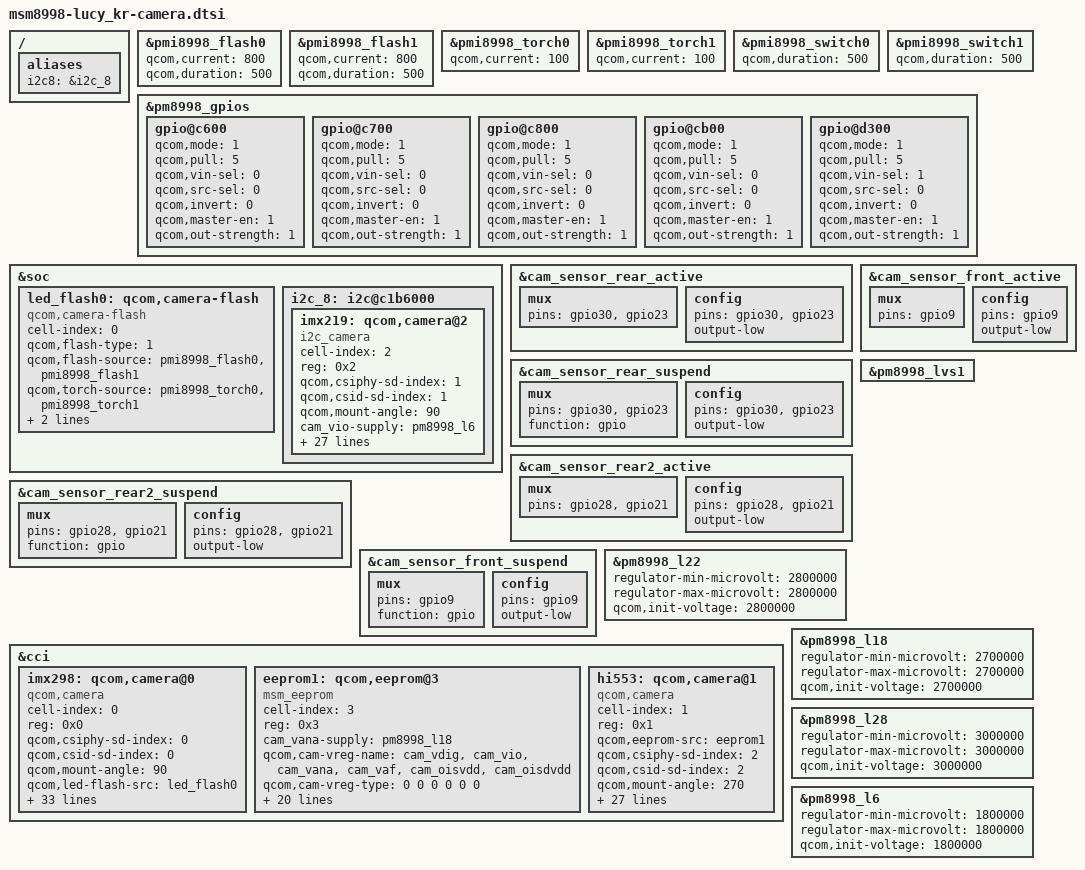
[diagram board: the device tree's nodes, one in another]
/*
 * Copyright (c) 2016, The Linux Foundation. All rights reserved.
 *
 * This program is free software; you can redistribute it and/or modify
 * it under the terms of the GNU General Public License version 2 and
 * only version 2 as published by the Free Software Foundation.
 *
 * This program is distributed in the hope that it will be useful,
 * but WITHOUT ANY WARRANTY; without even the implied warranty of
 * MERCHANTABILITY or FITNESS FOR A PARTICULAR PURPOSE.  See the
 * GNU General Public License for more details.
 */

/* Flash setting*/

&pmi8998_flash0 {
	qcom,current = <800>;
	qcom,duration = <500>;
};

&pmi8998_flash1 {
	qcom,current = <800>;
	qcom,duration = <500>;
};

&pmi8998_torch0 {
	qcom,current = <100>;
};

&pmi8998_torch1 {
	qcom,current = <100>;
};

&pmi8998_switch0 {
	qcom,duration = <500>;
};

&pmi8998_switch1 {
	qcom,duration = <500>;
};

/* PM8998 GPIO Settings */
&pm8998_gpios {
	gpio@c600 { /* GPIO 7 */
		qcom,mode = <1>;		/* Output */
		qcom,pull = <5>;		/* No Pull */
		qcom,vin-sel = <0>;		/* VIN1 GPIO_LV */
		qcom,src-sel = <0>;		/* GPIO */
		qcom,invert = <0>;		/* Invert */
		qcom,master-en = <1>;		/* Enable GPIO */
		qcom,out-strength = <1>;
		status = "ok";
	};
	gpio@c700 { /* GPIO 8 */
		qcom,mode = <1>;		/* Output */
		qcom,pull = <5>;		/* No Pull */
		qcom,vin-sel = <0>;		/* VIN1 GPIO_LV */
		qcom,src-sel = <0>;		/* GPIO */
		qcom,invert = <0>;		/* Invert */
		qcom,master-en = <1>;		/* Enable GPIO */
		qcom,out-strength = <1>;
		status = "ok";
	};
	gpio@c800 { /* GPIO 9 */
		qcom,mode = <1>;		/* Output */
		qcom,pull = <5>;		/* No Pull */
		qcom,vin-sel = <0>;		/* VIN1 GPIO_LV */
		qcom,src-sel = <0>;		/* GPIO */
		qcom,invert = <0>;		/* Invert */
		qcom,master-en = <1>;		/* Enable GPIO */
		qcom,out-strength = <1>;
		status = "ok";
	};
	gpio@cb00 { /* GPIO 12 */
		qcom,mode = <1>;		/* Output */
		qcom,pull = <5>;		/* No Pull */
		qcom,vin-sel = <0>;		/* VIN1 GPIO_LV */
		qcom,src-sel = <0>;		/* GPIO */
		qcom,invert = <0>;		/* Invert */
		qcom,master-en = <1>;		/* Enable GPIO */
		qcom,out-strength = <1>;
		status = "ok";
	};
	gpio@d300 { /* GPIO 20 */
		qcom,mode = <1>;		/* Output */
		qcom,pull = <5>;		/* No Pull */
		qcom,vin-sel = <1>;		/* VIN1 GPIO_MV */
		qcom,src-sel = <0>;		/* GPIO */
		qcom,invert = <0>;		/* Invert */
		qcom,master-en = <1>;		/* Enable GPIO */
		qcom,out-strength = <1>;
		status = "ok";
	};
};

&soc {
	led_flash0: qcom,camera-flash {
		cell-index = <0>;
		compatible = "qcom,camera-flash";
		qcom,flash-type = <1>;
		qcom,flash-source = <&pmi8998_flash0 &pmi8998_flash1>;
		qcom,torch-source = <&pmi8998_torch0 &pmi8998_torch1>;
		qcom,switch-source = <&pmi8998_switch0 &pmi8998_switch1>;
		status = "ok";
	};
};

/* PIN settings */
&cam_sensor_rear_active{
	/* CAM RESET, OIS RESET, OIS MVDD, CAM VDIG, CAM AVDD */
	mux {
		pins = "gpio30", "gpio23";
	};

	config {
		pins = "gpio30", "gpio23";
		output-low;
	};
};

&cam_sensor_rear_suspend{
	/* CAM RESET, OIS RESET, OIS MVDD, CAM VDIG, CAM AVDD */
	mux {
		pins = "gpio30", "gpio23";
		function = "gpio";
	};

	config {
		pins = "gpio30", "gpio23";
		output-low;
	};
};

&cam_sensor_rear2_active {
	/* RESET, VDIG */
	mux {
		pins = "gpio28", "gpio21";
	};

	config {
		pins = "gpio28", "gpio21";
		output-low;
	};
};

&cam_sensor_rear2_suspend {
	/* RESET, VDIG */
	mux {
		pins = "gpio28", "gpio21";
		function = "gpio";
	};

	config {
		pins = "gpio28", "gpio21";
		output-low;
	};
};

&cam_sensor_front_active {
	/* RESET, CAM_VDIG */
	mux {
		pins = "gpio9";
	};

	config {
		pins = "gpio9";
		output-low;
	};
};

&cam_sensor_front_suspend {
	/* RESET, CAM_VDIG */
	mux {
		pins = "gpio9";
		function = "gpio";
	};

	config {
		pins = "gpio9";
		output-low;
	};
};

/* 16M Rear camera */
&pm8998_lvs1 {
	status = "ok";
};

&pm8998_l22 {
	regulator-min-microvolt = <2800000>;
	regulator-max-microvolt = <2800000>;
	qcom,init-voltage = <2800000>;
	status = "okay";
};

&cci {
/*	ois: qcom,ois@0 {
		cell-index      = <0>;
		reg             = <0x0>;
		compatible      = "qcom,ois";
		qcom,cci-master = <0>;
	};

	proxy0: qcom,proxy@29 {
		status = "ok";
		cell-index = <0>;
		reg = <0x29 0x0>;
		compatible = "qcom,proxy";
		qcom,cci-master = <0>;
	};

	actuator0: qcom,actuator@0 {
		status = "ok";
		cell-index = <0>;
		reg = <0x0>;
		compatible = "qcom,actuator";
		qcom,cci-master = <0>;

		cam_vio-supply = <&pm8998_lvs1>;
		qcom,cam-vreg-name = "cam_vio";
		qcom,cam-vreg-min-voltage = <1800000>;
		qcom,cam-vreg-max-voltage = <1800000>;
		qcom,cam-vreg-op-mode = <2800>;

		gpios = <&tlmm 8 0>;
		qcom,gpio-vaf = <0>;
		qcom,gpio-req-tbl-num = <0>;
		qcom,gpio-req-tbl-flags = <0>;
		qcom,gpio-req-tbl-label = "CAM_VAF";

		pinctrl-names = "cam_default", "cam_suspend";
		pinctrl-0 = <&cam_actuator_vaf_active>;
		pinctrl-1 = <&cam_actuator_vaf_suspend>;
	};

	eeprom0: qcom,eeprom@0 {
		status = "ok";
		cell-index = <0>;
		reg = <0>;
		compatible = "qcom,eeprom";
		qcom,cci-master = <0>;

		cam_vio-supply = <&pm8998_lvs1>;
		cam_oisvdd-supply  = <&pm8998_l22>;

		qcom,cam-vreg-name = "cam_vdig", "cam_vio", "cam_vana", "cam_vaf", "cam_oisvdd", "cam_oisdvdd";
		qcom,cam-vreg-min-voltage = <0 1800000 0 0 2800000 0>;
		qcom,cam-vreg-max-voltage = <0 1800000 0 0 2800000 0>;
		qcom,cam-vreg-op-mode     = <0 2800 0 0 50000 0>;
		qcom,gpio-no-mux = <0>;
		pinctrl-names = "cam_default", "cam_suspend";
		pinctrl-0 = <&cam_sensor_mclk0_active &cam_sensor_rear_active>;
		pinctrl-1 = <&cam_sensor_mclk0_suspend
				 &cam_sensor_rear_suspend>;

		gpios = <&tlmm 13 0>,
		  <&tlmm 30 0>,
		  <&pm8998_gpios 7 0>; //16M_OIS_MVDD_EN

		qcom,gpio-req-tbl-num = <0 0 0>;
		qcom,gpio-req-tbl-flags = <1 0 0>;
		qcom,gpio-req-tbl-label = "CAMIF_MCLK0", "CAM0_RESET", "CAM_OISDVDD";

		clocks = <&clock_mmss clk_mclk0_clk_src>,
				<&clock_mmss clk_mmss_camss_mclk0_clk>;
		clock-names = "cam_src_clk", "cam_clk";
		qcom,clock-rates = <24000000 0>;
	};
*/
	imx298: qcom,camera@0 {
		cell-index = <0>;
		compatible = "qcom,camera";
		reg = <0x0>;
		qcom,csiphy-sd-index = <0>;
		qcom,csid-sd-index = <0>;
		qcom,mount-angle = <90>;
		qcom,led-flash-src = <&led_flash0>;
		//qcom,actuator-src  = <&actuator0>;
		//qcom,eeprom-src    = <&eeprom0>;
		//qcom,ois-src       = <&ois>;

		cam_vio-supply = <&pm8998_lvs1>;
		cam_oisvdd-supply  = <&pm8998_l22>;

		qcom,cam-vreg-name        = "cam_vdig", "cam_vio", "cam_vana", "cam_vaf", "cam_oisvdd", "cam_oisdvdd";
		qcom,cam-vreg-type        = <0 0 0 0 0 0>;
		qcom,cam-vreg-min-voltage = <0 1800000 0 0 2800000 0>;
		qcom,cam-vreg-max-voltage = <0 1800000 0 0 2800000 0>;
		qcom,cam-vreg-op-mode     = <0 2800 0 0 50000 0>;

		pinctrl-names = "cam_default", "cam_suspend";
		pinctrl-0 = <&cam_sensor_mclk0_active
				 &cam_sensor_rear_active>;
		pinctrl-1 = <&cam_sensor_mclk0_suspend
				 &cam_sensor_rear_suspend>;
		gpios = <&tlmm 13 0>,
			<&tlmm 30 0>,
			<&pm8998_gpios 20 0>, //16M_DVDD_EN
			<&tlmm 23 0>, //OIS_RESET_N
			<&pm8998_gpios 7 0>, //16M_OIS_MVDD_EN
			<&pm8998_gpios 8 0>; //16M_AVDD_EN
			//<&pmi8998_gpios 3 0>;

		qcom,gpio-no-mux    = <0>;
		qcom,gpio-reset     = <1>;
		qcom,gpio-vdig = <2>;
		qcom,gpio-ois-reset = <3>;
		qcom,gpio-oisdvdd  = <4>; //need to add in msm_camera_dt_util.c
		qcom,gpio-vana      = <5>;
		//qcom,gpio-ldaf-en   = <6>;

		qcom,gpio-req-tbl-num = <0 1 2 3 4 5>;
		qcom,gpio-req-tbl-flags = <1 0 0 0 0 0>;
		qcom,gpio-req-tbl-label = "CAMIF_MCLK0",
					  "CAM0_RESET",
					  "CAM0_VDIG",
					  "OIS_RESET",
					  "CAM_OISDVDD",
					  "CAM0_AVDD";
					  //"LDAF_EN";

		qcom,sensor-position = <0>;
		qcom,sensor-mode = <0>;
		qcom,cci-master = <0>;
		status = "ok";
		clocks = <&clock_mmss clk_mclk0_clk_src>,
				<&clock_mmss clk_mmss_camss_mclk0_clk>;
		clock-names = "cam_src_clk", "cam_clk";
		qcom,clock-rates = <24000000 0>;
	};
};

/* 8M Rear camera */

&pm8998_l18 {
	regulator-min-microvolt = <2700000>;
	regulator-max-microvolt = <2700000>;
	qcom,init-voltage = <2700000>;
	status = "okay";
};

&cci {
	eeprom1: qcom,eeprom@3 {
		status = "ok";
		cell-index = <3>;
		reg = <0x3>;
		compatible = "msm_eeprom";

		cam_vana-supply           = <&pm8998_l18>;

		qcom,cam-vreg-name        = "cam_vdig", "cam_vio", "cam_vana", "cam_vaf", "cam_oisvdd", "cam_oisdvdd";
		qcom,cam-vreg-type        = <0 0 0 0 0 0>;
		qcom,cam-vreg-min-voltage = <0 0 2700000 0 0 0>;
		qcom,cam-vreg-max-voltage = <0 0 2700000 0 0 0>;
		qcom,cam-vreg-op-mode     = < 0  0  36000 0 0 0>;

		pinctrl-names = "cam_default", "cam_suspend";
		pinctrl-0 = <&cam_sensor_mclk1_active &cam_sensor_front_active>;
		pinctrl-1 = <&cam_sensor_mclk1_suspend &cam_sensor_front_suspend>;

		gpios     = <&tlmm 14 0>,
			<&tlmm 9 0>,
			<&pm8998_gpios 9 0>,  //VT_DVDD_EN check
			<&pm8998_gpios 12 0>; //VT_IO_EN

		qcom,gpio-no-mux        = <0>;
		qcom,gpio-reset         = <1>;
		qcom,gpio-vdig =       <2>;
		qcom,gpio-vio= <3>;
		qcom,gpio-req-tbl-num   = <0 1 2 3>;
		qcom,gpio-req-tbl-flags = <1 0 0 0>;
		qcom,gpio-req-tbl-label = "CAMIF_MCLK1",
					  "VT_RESET",
					  "VT_VDIG",
					  "VT_VIO";

		clocks = <&clock_mmss clk_mclk2_clk_src>,
				 <&clock_mmss clk_mmss_camss_mclk2_clk>;
		clock-names = "cam_src_clk", "cam_clk";
		qcom,clock-rates = <24000000 0>;
	};


	hi553: qcom,camera@1 {
		cell-index = <1>;
		compatible = "qcom,camera";
		reg        = <0x1>;
		qcom,eeprom-src    = <&eeprom1>;

		qcom,csiphy-sd-index = <2>;
		qcom,csid-sd-index   = <2>;
		qcom,mount-angle     = <270>;

		cam_vana-supply           = <&pm8998_l18>;

		qcom,cam-vreg-name        = "cam_vdig", "cam_vio", "cam_vana", "cam_vaf", "cam_oisvdd", "cam_oisdvdd";
		qcom,cam-vreg-type        = <0 0 0 0 0 0>;
		qcom,cam-vreg-min-voltage = <0 0 2700000 0 0 0>;
		qcom,cam-vreg-max-voltage = <0 0 2700000 0 0 0>;
		qcom,cam-vreg-op-mode     = < 0  0  36000 0 0 0>;

		pinctrl-names = "cam_default", "cam_suspend";
		pinctrl-0 = <&cam_sensor_mclk1_active &cam_sensor_front_active>;
		pinctrl-1 = <&cam_sensor_mclk1_suspend &cam_sensor_front_suspend>;

		gpios     = <&tlmm 14 0>,
			<&tlmm 9 0>,
			<&pm8998_gpios 9 0>,  //VT_DVDD_EN check
			<&pm8998_gpios 12 0>; //VT_IO_EN

		qcom,gpio-no-mux        = <0>;
		qcom,gpio-reset         = <1>;
		qcom,gpio-vdig =       <2>;
		qcom,gpio-vio= <3>;
		qcom,gpio-req-tbl-num   = <0 1 2 3>;
		qcom,gpio-req-tbl-flags = <1 0 0 0>;
		qcom,gpio-req-tbl-label = "CAMIF_MCLK1",
					  "VT_RESET",
					  "VT_VDIG",
					  "VT_VIO";

		qcom,sensor-position = <1>;
		qcom,sensor-mode     = <0>;
		qcom,cci-master = <1>;
		status = "ok";
		clocks = <&clock_mmss clk_mclk1_clk_src>,
			<&clock_mmss clk_mmss_camss_mclk1_clk>;
		clock-names = "cam_src_clk", "cam_clk";
		qcom,clock-rates = <24000000 0>;
	};

};

/* 8M Front camera */
/{
	aliases {
		i2c8 = &i2c_8; //check
	};
};

&soc {
i2c_8: i2c@c1b6000 { /* BLSP2 QUP2 */
		status = "okay";
	};
};

&pm8998_l28 {
	regulator-min-microvolt = <3000000>;
	regulator-max-microvolt = <3000000>;
	qcom,init-voltage = <3000000>;
	status = "okay";
};

&pm8998_l6 {
	regulator-min-microvolt = <1800000>;
	regulator-max-microvolt = <1800000>;
	qcom,init-voltage = <1800000>;
	status = "okay";
};

&i2c_8 {
/*	eeprom2: qcom,eeprom@2 {
		status = "ok";
		cell-index = <2>;
		reg = <2>;
		compatible = "qcom,eeprom";

		//cam_vdig-supply    = <&pm8994_l11>;
		cam_vio-supply     = <&pm8998_l6>;
		cam_vana-supply = <&pm8998_l28>;

		qcom,cam-vreg-name        = "cam_vdig", "cam_vio", "cam_vana", "cam_vaf", "cam_oisvdd", "cam_oisdvdd", "cam_vi2c";
		qcom,cam-vreg-type        = <0 0 0 0 0 0 0>;
		qcom,cam-vreg-min-voltage = <0 1800000 3000000 0 0 0 0>;
		qcom,cam-vreg-max-voltage = <0 1800000 3000000 0 0 0 0>;
		qcom,cam-vreg-op-mode     = <0  500 38000 0 0 0 0 >;

		pinctrl-names = "cam_default", "cam_suspend";
		pinctrl-0 = <&cam_sensor_mclk2_active &cam_sensor_rear2_active>;
		pinctrl-1 = <&cam_sensor_mclk2_suspend &cam_sensor_rear2_suspend>;

		gpios = <&tlmm 15 0>,
		        <&tlmm 28 0>,
		        <&tlmm 21 0>;

		qcom,gpio-no-mux    = <0>;
		qcom,gpio-reset     = <1>;
		qcom,gpio-vdig      = <2>;

		qcom,gpio-req-tbl-num   = <0 1 2>;
		qcom,gpio-req-tbl-flags = <1 0 0>;
		qcom,gpio-req-tbl-label = "CAMIF_MCLK2",
		                          "CAM1_RESET",
		                          "CAM1_DVDD";

		clocks = <&clock_mmss clk_mclk2_clk_src>,
				 <&clock_mmss clk_mmss_camss_mclk2_clk>;
		clock-names = "cam_src_clk", "cam_clk";
		qcom,clock-rates = <24000000 0>;
	};
*/
	imx219: qcom,camera@2 {
		cell-index = <2>;
		compatible = "i2c_camera";
		reg        = <0x2>;

		qcom,csiphy-sd-index = <1>;
		qcom,csid-sd-index   = <1>;
		qcom,mount-angle     = <90>;

		//qcom,eeprom-src    = <&eeprom2>;

		//cam_vdig-supply    = <&pm8994_l11>;
		cam_vio-supply     = <&pm8998_l6>;
		cam_vana-supply = <&pm8998_l28>;

		qcom,cam-vreg-name        = "cam_vdig", "cam_vio", "cam_vana", "cam_vaf", "cam_oisvdd", "cam_oisdvdd", "cam_vi2c";
		qcom,cam-vreg-type        = <0 0 0 0 0 0 0>;
		qcom,cam-vreg-min-voltage = <0 1800000 3000000 0 0 0 0>;
		qcom,cam-vreg-max-voltage = <0 1800000 3000000 0 0 0 0>;
		qcom,cam-vreg-op-mode     = <0  500 38000 0 0 0 0 >;

		pinctrl-names = "cam_default", "cam_suspend";
		pinctrl-0 = <&cam_sensor_mclk2_active &cam_sensor_rear2_active>;
		pinctrl-1 = <&cam_sensor_mclk2_suspend &cam_sensor_rear2_suspend>;

		gpios = <&tlmm 15 0>,
		        <&tlmm 28 0>,
		        <&tlmm 21 0>;

		qcom,gpio-no-mux    = <0>;
		qcom,gpio-reset     = <1>;
		qcom,gpio-vdig      = <2>;

		qcom,gpio-req-tbl-num   = <0 1 2>;
		qcom,gpio-req-tbl-flags = <1 0 0>;
		qcom,gpio-req-tbl-label = "CAMIF_MCLK2",
		                          "CAM1_RESET",
		                          "CAM1_DVDD";

		qcom,sensor-position = <0>;
		qcom,sensor-mode = <0>;
		status = "ok";
		clocks = <&clock_mmss clk_mclk2_clk_src>,
				 <&clock_mmss clk_mmss_camss_mclk2_clk>;
		clock-names = "cam_src_clk", "cam_clk";
		qcom,clock-rates = <24000000 0>;
	};
};
